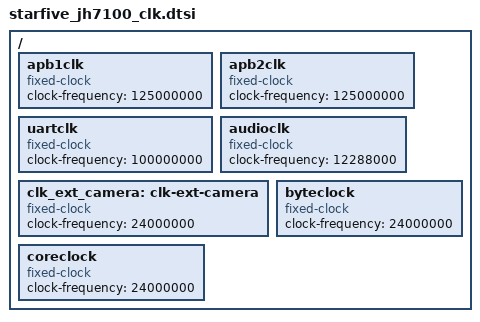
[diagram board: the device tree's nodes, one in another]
/* SPDX-License-Identifier: GPL-2.0-or-later */
/* Copyright (c) 2021 StarFive Technology Co., Ltd. */

/ {
	apb1clk: apb1clk {
		#clock-cells = <0>;
		compatible = "fixed-clock";
		clock-frequency = <125000000>;
	};
	apb2clk: apb2clk {
		#clock-cells = <0>;
		compatible = "fixed-clock";
		clock-frequency = <125000000>;
	};
	uartclk: uartclk {
		#clock-cells = <0>;
		compatible = "fixed-clock";
		clock-frequency = <100000000>;
	};
	audioclk: audioclk {
		#clock-cells = <0>;
		compatible = "fixed-clock";
		clock-frequency = <12288000>;
	};
	clk_ext_camera: clk-ext-camera {
		#clock-cells = <0>;
		compatible = "fixed-clock";
		clock-frequency = <24000000>;
	};
	byteclock: byteclock {
		#clock-cells = <0>;
		compatible = "fixed-clock";
		clock-frequency = <24000000>;
	};
	coreclock: coreclock {
		#clock-cells = <0>;
		compatible = "fixed-clock";
		clock-frequency = <24000000>;
	};
};
